# MDR1986BE3T register map
Vendor: Milandr; File version: 1.0
CPU: CM1 r0p0, little endian, no MPU, no FPU, 3 interrupt priority bits
Registers are 32-bit, read-write, reset 0x0 unless marked. A register's access mark holds for its fields unless they carry their own. Offsets are from the block's base; [hi:lo] are bit positions; {n}, {i} and the like mark numbered series.

## MDR_DAC — DAC
Base 0x40090000; register names take the prefix MDR_DAC_
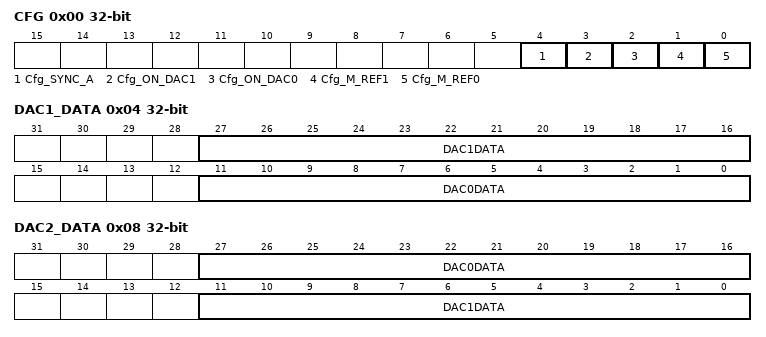
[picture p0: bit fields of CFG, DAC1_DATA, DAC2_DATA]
0x00 CFG — DAC Configuration Register
  [4] Cfg_SYNC_A, [3] Cfg_ON_DAC1, [2] Cfg_ON_DAC0, [1] Cfg_M_REF1, [0] Cfg_M_REF0
0x04 DAC1_DATA
  [27:16] DAC1DATA, [11:0] DAC0DATA
0x08 DAC2_DATA
  [27:16] DAC0DATA, [11:0] DAC1DATA

## MDR_PORTA — PORTA
Base 0x400A8000; register names take the prefix MDR_PORTA_
Same registers: MDR_PORTB 0x400B0000 (register names take the prefix MDR_PORTB_), MDR_PORTC 0x400B8000 (register names take the prefix MDR_PORTC_), MDR_PORTD 0x400C0000 (register names take the prefix MDR_PORTD_), MDR_PORTE 0x400C8000 (register names take the prefix MDR_PORTE_), MDR_PORTF 0x400E8000 (register names take the prefix MDR_PORTF_), MDR_PORTG 0x40118000 (register names take the prefix MDR_PORTG_), MDR_PORTH 0x40138000 (register names take the prefix MDR_PORTH_), MDR_PORTI 0x40140000 (register names take the prefix MDR_PORTI_)
0x00 RXTX — PORT Data Register
  [15:0] RXTX
0x04 OE — PORT Output Enable Register
  [15:0] OE
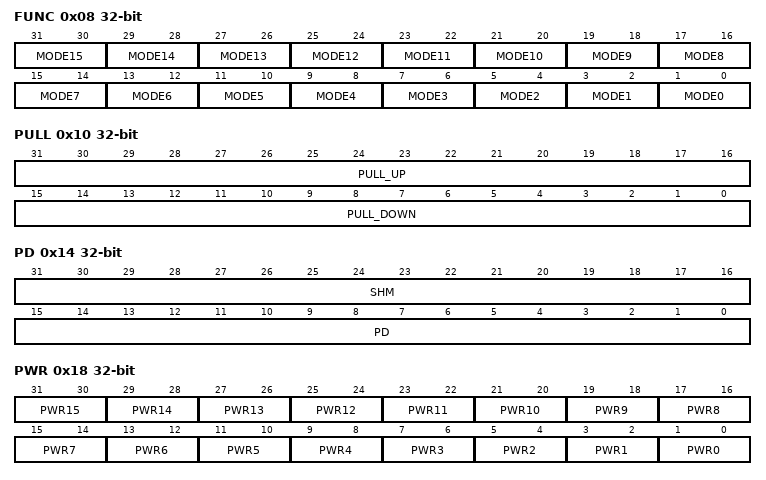
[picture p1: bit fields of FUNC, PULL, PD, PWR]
0x08 FUNC — PORT Function Register
  [2n+1:2n] MODE{n} (n=0..15)
0x0C ANALOG — PORT Analog Function Register
  [15:0] ANALOG_EN
0x10 PULL — PORT Pull Up/Down Register
  [31:16] PULL_UP, [15:0] PULL_DOWN
0x14 PD — PORT Driver Mode Register
  [31:16] SHM, [15:0] PD
0x18 PWR — PORT Power Register
  [2n+1:2n] PWR{n} (n=0..15)
0x1C GFEN — PORT Filter Configuration Register
  [15:0] GFEN
0x20 SETTX — Set Pin in function PORT
  [15:0] SetTX
0x24 CLRTX — Clear Pin in function PORT
  [15:0] ClearTX
0x28 RDTX ro — Read Pin out in function PORT
  [15:0] ReadTX rw

## MDR_ARINCR — ARINC429R
Base 0x400D0000; register names take the prefix MDR_ARINCR_
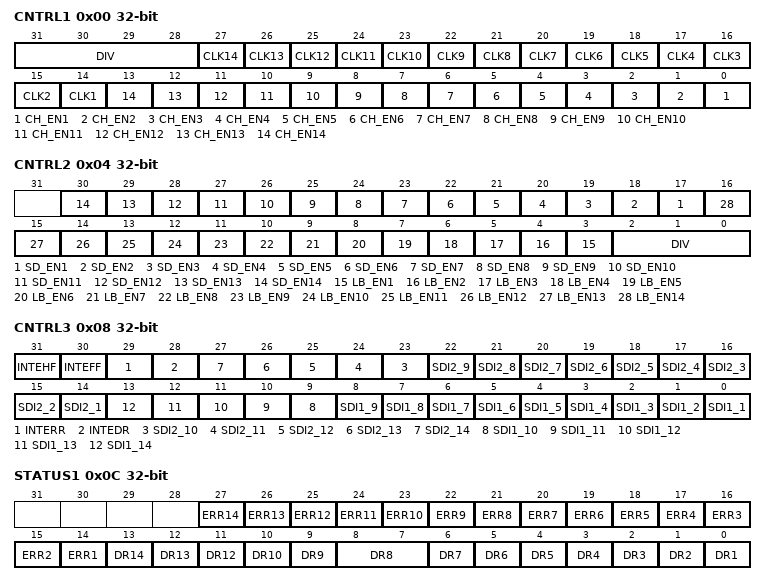
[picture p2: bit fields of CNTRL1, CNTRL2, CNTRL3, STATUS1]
0x00 CNTRL1
  [31:28] DIV, [n+13] CLK{n} (n=1..14), [n-1] CH_EN{n} (n=1..14)
0x04 CNTRL2
  [n+16] SD_EN{n} (n=1..14), [n+2] LB_EN{n} (n=1..14), [2:0] DIV
0x08 CNTRL3
  [31] INTEHF, [30] INTEFF, [29] INTERR, [28] INTEDR, [n+13] SDI2_{n} (n=1..14), [n-1] SDI1_{n} (n=1..14)
0x0C STATUS1
  [n+13] ERR{n} (n=1..14), [13] DR14, [12] DR13, [11] DR12, [10] DR10, [9] DR9, [8:7] DR8, [n-1] DR{n} (n=1..7)
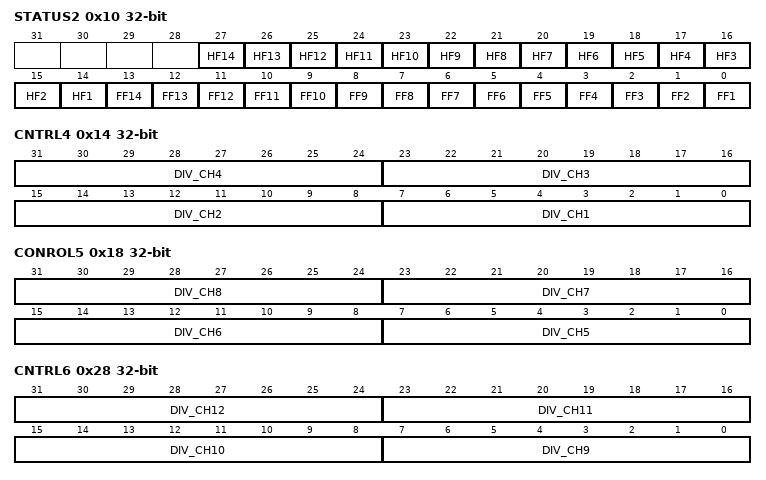
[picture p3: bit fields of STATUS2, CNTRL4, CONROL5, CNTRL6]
0x10 STATUS2
  [n+13] HF{n} (n=1..14), [n-1] FF{n} (n=1..14)
0x14 CNTRL4
  [8n-1:8n-8] DIV_CH{n} (n=1..4)
0x18 CONROL5
  [8n-33:8n-40] DIV_CH{n} (n=5..8)
0x1C CHANNEL
  [3:0] CHAN
0x20 LABLE
0x24 DATA_R
0x28 CNTRL6
  [8n-65:8n-72] DIV_CH{n} (n=9..12)
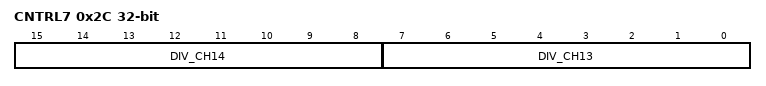
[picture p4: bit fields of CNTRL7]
0x2C CNTRL7
  [15:8] DIV_CH14, [7:0] DIV_CH13

## MDR_BKP — BACKUP
Base 0x400D8000; register names take the prefix MDR_BKP_
{0x0+4i} REG_{i:02} (i=0..9) — Backup Register {i}
  [31:0] BKP_REG
0x28 REG_0A — Backup Register 10
  [31:0] BKP_REG
0x2C REG_0B — Backup Register 11
  [31:0] BKP_REG
0x30 REG_0C — Backup Register 12
  [31:0] BKP_REG
0x34 REG_0D — Backup Register 13
  [31:0] BKP_REG
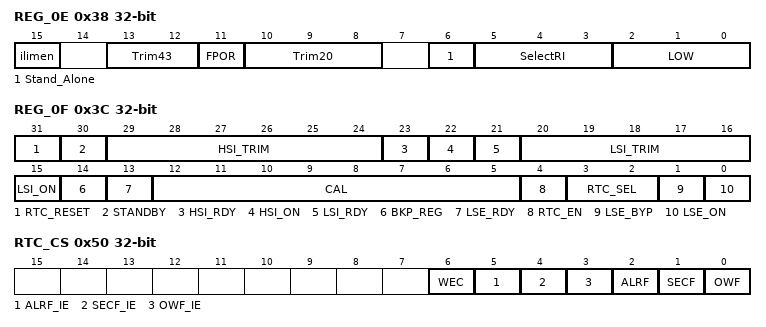
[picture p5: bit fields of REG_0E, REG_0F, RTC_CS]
0x38 REG_0E — Backup Register 14
  [15] ilimen, [13:12] Trim43, [11] FPOR, [10:8] Trim20, [6] Stand_Alone, [5:3] SelectRI, [2:0] LOW
0x3C REG_0F — Backup Register 15
  [31] RTC_RESET, [30] STANDBY, [29:24] HSI_TRIM, [23] HSI_RDY, [22] HSI_ON, [21] LSI_RDY, [20:16] LSI_TRIM, [15] LSI_ON, [14] BKP_REG, [13] LSE_RDY, [12:5] CAL, [4] RTC_EN, [3:2] RTC_SEL, [1] LSE_BYP, [0] LSE_ON
0x40 RTC_CNT — Realtime Clock Counter Register
0x44 RTC_DIV — Realtime Prescaler Counter Register
  [19:0] RTC_DIV
0x48 RTC_PRL — Realtime Prescaler Auto-Reload Value Register
  [19:0] RTC_PRL
0x4C RTC_ALRM — Realtime Alarm Register
0x50 RTC_CS — Backup Realtime clock Register
  [6] WEC, [5] ALRF_IE, [4] SECF_IE, [3] OWF_IE, [2] ALRF, [1] SECF, [0] OWF

## MDR_ARINCT — ARINC429T
Base 0x400E0000; register names take the prefix MDR_ARINCT_
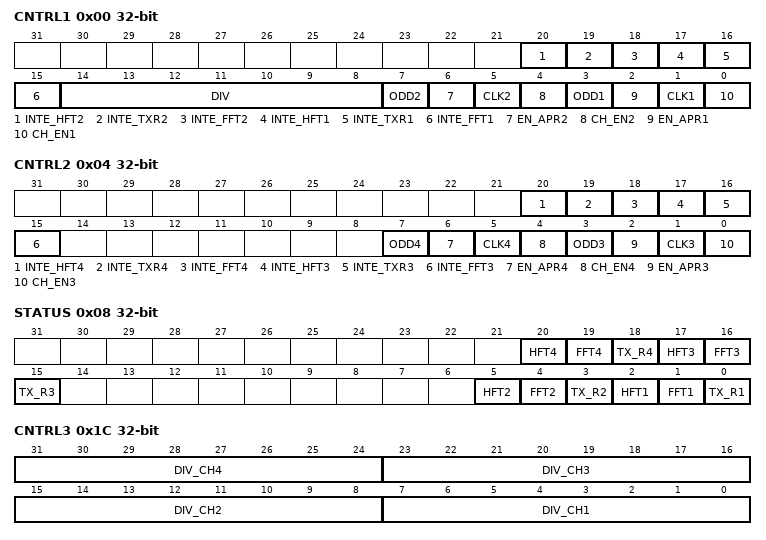
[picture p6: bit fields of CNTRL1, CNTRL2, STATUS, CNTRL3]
0x00 CNTRL1
  [20] INTE_HFT2, [19] INTE_TXR2, [18] INTE_FFT2, [17] INTE_HFT1, [16] INTE_TXR1, [15] INTE_FFT1, [14:8] DIV, [7] ODD2, [6] EN_APR2, [5] CLK2, [4] CH_EN2, [3] ODD1, [2] EN_APR1, [1] CLK1, [0] CH_EN1
0x04 CNTRL2
  [20] INTE_HFT4, [19] INTE_TXR4, [18] INTE_FFT4, [17] INTE_HFT3, [16] INTE_TXR3, [15] INTE_FFT3, [7] ODD4, [6] EN_APR4, [5] CLK4, [4] CH_EN4, [3] ODD3, [2] EN_APR3, [1] CLK3, [0] CH_EN3
0x08 STATUS
  [20] HFT4, [19] FFT4, [18] TX_R4, [17] HFT3, [16] FFT3, [15] TX_R3, [5] HFT2, [4] FFT2, [3] TX_R2, [2] HFT1, [1] FFT1, [0] TX_R1
{0x8+4i} DATA{i}_T (i=1..4)
0x1C CNTRL3
  [8n-1:8n-8] DIV_CH{n} (n=1..4)
